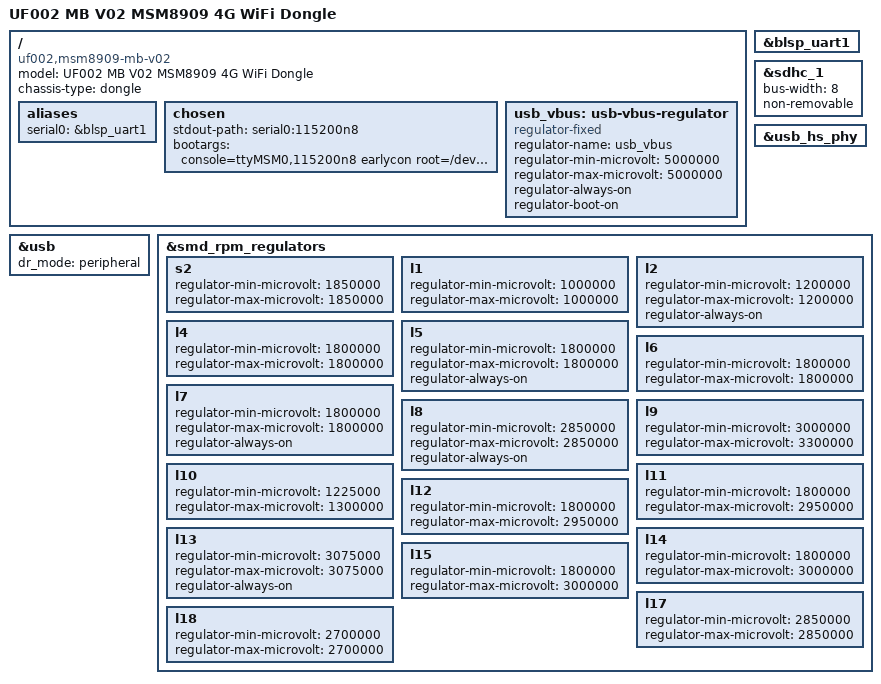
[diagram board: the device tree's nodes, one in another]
// SPDX-License-Identifier: GPL-2.0-only
/*
 * Device Tree Source for UF002 / YL_UF002 4G LTE USB Dongle
 * PCB: UF002_MB_V02 (20230327)
 * SoC: Qualcomm MSM8909 (Snapdragon 210)
 * PMIC: PM8909
 * eMMC: 4GB Kingston 04EMCP04
 * RAM: 512MB LPDDR3
 *
 * Regulator mapping (from stock Android 3.10 live hardware inspection):
 *   USB VDD_DIG   -> PM8909_L2  @ 1.2V
 *   USB HSUSB_1p8 -> PM8909_L7  @ 1.8V
 *   USB HSUSB_3p3 -> PM8909_L13 @ 3.075V
 *   eMMC vdd-io   -> PM8909_L5  @ 1.8V
 *   eMMC vdd      -> PM8909_L8  @ 2.85V
 *   WCNSS vddxo   -> PM8909_L7  @ 1.8V
 */

/dts-v1/;

#include "qcom-msm8909-pm8909.dtsi"

/ {
	model = "UF002 MB V02 MSM8909 4G WiFi Dongle";
	compatible = "uf002,msm8909-mb-v02", "qcom,msm8909";
	chassis-type = "dongle";

	aliases {
		serial0 = &blsp_uart1;
	};

	chosen {
		stdout-path = "serial0:115200n8";
		bootargs = "console=ttyMSM0,115200n8 earlycon root=/dev/mmcblk0p21 rw rootwait";
	};

	/*
	 * USB VBUS regulator - dongle operates purely in gadget/peripheral mode.
	 */
	usb_vbus: usb-vbus-regulator {
		compatible = "regulator-fixed";
		regulator-name = "usb_vbus";
		regulator-min-microvolt = <5000000>;
		regulator-max-microvolt = <5000000>;
		regulator-always-on;
		regulator-boot-on;
	};
};

/* UART debug console */
&blsp_uart1 {
	status = "okay";
};

/* eMMC storage (Kingston 04EMCP04 4GB) */
&sdhc_1 {
	status = "okay";
	bus-width = <8>;
	non-removable;
};

/* USB 2.0 Gadget Controller */
&usb {
	dr_mode = "peripheral";
	status = "okay";
};

&usb_hs_phy {
	status = "okay";
};

/* Voltage Regulators from PM8909 */
&smd_rpm_regulators {
	s2 {
		regulator-min-microvolt = <1850000>;
		regulator-max-microvolt = <1850000>;
	};

	l1 {
		regulator-min-microvolt = <1000000>;
		regulator-max-microvolt = <1000000>;
	};

	/* USB VDD_DIG: 1.2V */
	l2 {
		regulator-min-microvolt = <1200000>;
		regulator-max-microvolt = <1200000>;
		regulator-always-on;
	};

	l4 {
		regulator-min-microvolt = <1800000>;
		regulator-max-microvolt = <1800000>;
	};

	/* eMMC vqmmc / IO: 1.8V */
	l5 {
		regulator-min-microvolt = <1800000>;
		regulator-max-microvolt = <1800000>;
		regulator-always-on;
	};

	l6 {
		regulator-min-microvolt = <1800000>;
		regulator-max-microvolt = <1800000>;
	};

	/* USB HSUSB_1p8 & WCNSS vddxo: 1.8V */
	l7 {
		regulator-min-microvolt = <1800000>;
		regulator-max-microvolt = <1800000>;
		regulator-always-on;
	};

	/* eMMC vmmc / Core: 2.85V */
	l8 {
		regulator-min-microvolt = <2850000>;
		regulator-max-microvolt = <2850000>;
		regulator-always-on;
	};

	l9 {
		regulator-min-microvolt = <3000000>;
		regulator-max-microvolt = <3300000>;
	};

	l10 {
		regulator-min-microvolt = <1225000>;
		regulator-max-microvolt = <1300000>;
	};

	l11 {
		regulator-min-microvolt = <1800000>;
		regulator-max-microvolt = <2950000>;
	};

	l12 {
		regulator-min-microvolt = <1800000>;
		regulator-max-microvolt = <2950000>;
	};

	/* USB HSUSB_3p3: 3.075V */
	l13 {
		regulator-min-microvolt = <3075000>;
		regulator-max-microvolt = <3075000>;
		regulator-always-on;
	};

	l14 {
		regulator-min-microvolt = <1800000>;
		regulator-max-microvolt = <3000000>;
	};

	l15 {
		regulator-min-microvolt = <1800000>;
		regulator-max-microvolt = <3000000>;
	};

	l17 {
		regulator-min-microvolt = <2850000>;
		regulator-max-microvolt = <2850000>;
	};

	l18 {
		regulator-min-microvolt = <2700000>;
		regulator-max-microvolt = <2700000>;
	};
};
